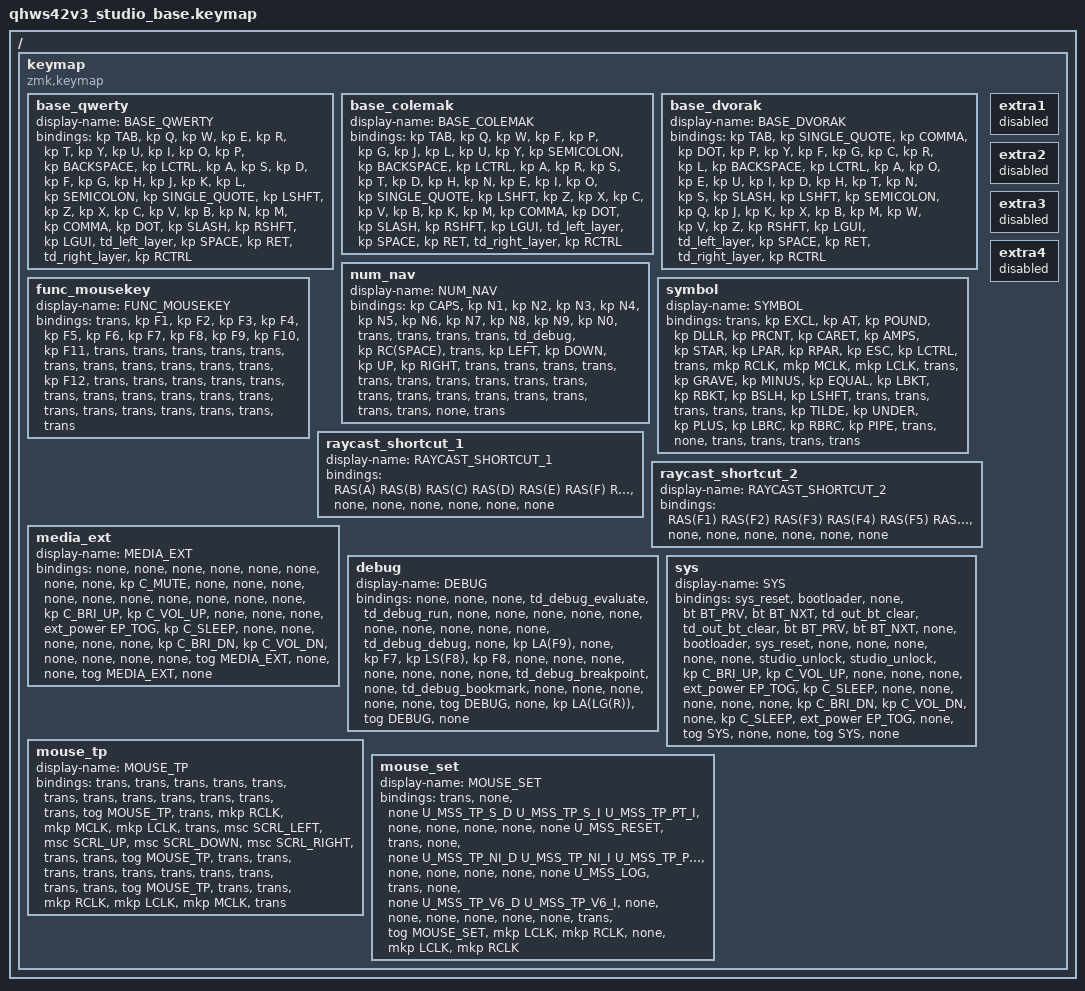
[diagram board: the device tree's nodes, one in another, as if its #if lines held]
/*
 * Copyright (c) 2020 The ZMK Contributors
 *
 * SPDX-License-Identifier: MIT
 */

// Define layer numbers
#define BASE_QWERTY 0
#define BASE_COLEMAK 1
#define BASE_DVORAK 2

#define NUM_NAV 3
#define SYMBOL 4
#define FUNC_MOUSEKEY 5

#define RAYCAST_SHORTCUT_1 6
#define RAYCAST_SHORTCUT_2 7

// 亮度，声音，macro
#define MEDIA_EXT 8
// idea debug
#define DEBUG 9
#define SYS 10

#define MOUSE_TP 11
#define MOUSE_SET 12


// ZMK includes
#include <behaviors.dtsi>
#include <dt-bindings/zmk/keys.h>
#include <dt-bindings/zmk/bt.h>
#include <dt-bindings/zmk/rgb.h>
#include <dt-bindings/zmk/ext_power.h>


// Personal includes
// #ifdef HAS_MOUSE_KEYS
//      #include "includes/mouse_keys.dtsi"
// #endif
// 
// #ifdef HAS_MOUSE_TP
//      #include "includes/mouse_tp.dtsi"
// #endif
#ifdef HAS_MOUSE_KEYS
    #include <dt-bindings/zmk/mouse.h>
#endif

// #include "includes/custom_keycodes.dtsi"
#include "includes/settings.dtsi"
//#include "includes/settings_pd.dtsi"
// #include "includes/conditional_layers.dtsi"
// #include "includes/macros.dtsi"
// #include "includes/combos.dtsi"
// #include "includes/behaviours_homerow_mods.dtsi"
// #include "includes/behaviours_mod_morph.dtsi"
// #include "includes/behaviours_other.dtsi"


#include "includes/qh_conditional_layers_v2.dtsi"
#include "includes/qh_combos_v2.dtsi"
#include "includes/qh_behaviours_other_v2.dtsi"

// raycast shortcut
#define RAS(X)  &kp LS(LC(LA(LG(X))))

// &none            &none           &none           &none           &none           &none               &none           &none           &none           &none           &none           &none
// &none            &none           &none           &none           &none           &none               &none           &none           &none           &none           &none           &none
// &none            &none           &none           &none           &none           &none               &none           &none           &none           &none           &none           &none
//                                                  &none           &none           &none               &none           &none           &none

// &tran            &trans          &trans          &trans          &trans          &trans              &trans          &trans          &trans          &trans          &trans          &trans
// &tran            &trans          &trans          &trans          &trans          &trans              &trans          &trans          &trans          &trans          &trans          &trans
// &tran            &trans          &trans          &trans          &trans          &trans              &trans          &trans          &trans          &trans          &trans          &trans
//                                                  &trans          &trans          &trans              &trans          &trans          &trans

/ {

  keymap {
    compatible = "zmk,keymap";

        base_qwerty {
            display-name = "BASE_QWERTY";
            bindings = <
                &kp TAB    &kp Q  &kp W     &kp E     &kp R                     &kp T               &kp Y    &kp U              &kp I      &kp O    &kp P          &kp BACKSPACE
                &kp LCTRL  &kp A  &kp S     &kp D     &kp F                     &kp G               &kp H    &kp J              &kp K      &kp L    &kp SEMICOLON  &kp SINGLE_QUOTE
                &kp LSHFT  &kp Z  &kp X     &kp C     &kp V                     &kp B               &kp N    &kp M              &kp COMMA  &kp DOT  &kp SLASH      &kp RSHFT
                                            &kp LGUI  &td_left_layer            &kp SPACE           &kp RET  &td_right_layer    &kp RCTRL
            >;
        };

        base_colemak {
            display-name = "BASE_COLEMAK";
            bindings = <
                &kp TAB    &kp Q  &kp W     &kp F     &kp P                     &kp G               &kp J    &kp L              &kp U      &kp Y    &kp SEMICOLON   &kp BACKSPACE
                &kp LCTRL  &kp A  &kp R     &kp S     &kp T                     &kp D               &kp H    &kp N              &kp E      &kp I    &kp O           &kp SINGLE_QUOTE
                &kp LSHFT  &kp Z  &kp X     &kp C     &kp V                     &kp B               &kp K    &kp M              &kp COMMA  &kp DOT  &kp SLASH       &kp RSHFT
                                            &kp LGUI  &td_left_layer            &kp SPACE           &kp RET  &td_right_layer    &kp RCTRL
            >;
        };

        base_dvorak {
            display-name = "BASE_DVORAK";
            bindings = <
                &kp TAB    &kp SINGLE_QUOTE &kp COMMA   &kp DOT   &kp P         &kp Y               &kp F    &kp G                  &kp C      &kp R  &kp L  &kp BACKSPACE
                &kp LCTRL  &kp A            &kp O       &kp E     &kp U         &kp I               &kp D    &kp H                  &kp T      &kp N  &kp S  &kp SLASH
                &kp LSHFT  &kp SEMICOLON    &kp Q       &kp J     &kp K         &kp X               &kp B    &kp M                  &kp W      &kp V  &kp Z  &kp RSHFT
                                            &kp LGUI    &td_left_layer          &kp SPACE           &kp RET  &td_right_layer    &kp RCTRL
            >;
        };

        num_nav {
            display-name = "NUM_NAV";
            bindings = <
                &kp CAPS    &kp N1      &kp N2      &kp N3       &kp N4        &kp N5          &kp N6    &kp N7    &kp N8     &kp N9     &kp N0  &trans
                &trans      &trans      &trans      &td_debug    &kp RC(SPACE) &trans          &kp LEFT  &kp DOWN  &kp UP     &kp RIGHT  &trans  &trans
                &trans      &trans      &trans      &trans       &trans        &trans          &trans    &trans    &trans     &trans     &trans  &trans
                                                    &trans       &trans        &trans          &trans    &none    &trans
            >;
        };

#ifdef HAS_MOUSE_KEYS
        symbol {
            display-name = "SYMBOL";
            bindings = <
                &trans      &kp EXCL      &kp AT      &kp POUND     &kp DLLR      &kp PRCNT                 &kp CARET       &kp AMPS        &kp STAR    &kp LPAR    &kp RPAR    &kp ESC
                &kp LCTRL   &trans        &mkp RCLK   &mkp MCLK     &mkp LCLK     &trans                    &kp GRAVE       &kp MINUS       &kp EQUAL   &kp LBKT    &kp RBKT    &kp BSLH
                &kp LSHFT   &trans        &trans      &trans        &trans        &trans                    &kp TILDE       &kp UNDER       &kp PLUS    &kp LBRC    &kp RBRC    &kp PIPE
                                                      &trans        &none        &trans                    &trans          &trans          &trans
            >;
        };
        func_mousekey {
            display-name = "FUNC_MOUSEKEY";
            bindings = <
                &trans  &kp F1  &kp F2      &kp F3     &kp F4      &kp F5              &kp F6          &kp F7          &kp F8          &kp F9          &kp F10  &kp F11
                &trans  &trans  &trans      &trans     &trans      &trans              &trans          &trans          &trans          &trans          &trans   &kp F12
                &trans  &trans  &trans      &trans     &trans      &trans              &trans          &trans          &trans          &trans          &trans   &trans
                                            &trans      &trans      &trans             &trans          &trans          &trans
            >;
        };
#else
        symbol {
            display-name = "SYMBOL";
            bindings = <
                &trans      &kp LS(EXCL)  &kp LS(AT)  &kp LS(POUND)  &kp LS(DLLR)  &kp LS(PRCNT)        &kp LS(CARET)  &kp LS(AMPS)   &kp LS(STAR)  &kp LS(LPAR)        &kp LS(RPAR)       &kp ESC
                &kp LCTRL   &trans        &trans      &trans         &trans        &trans               &kp GRAVE      &kp MINUS      &kp EQUAL     &kp LBKT            &kp RIGHT_BRACKET  &kp BSLH
                &kp LSHFT   &trans        &trans      &trans         &trans        &trans               &kp LS(TILDE)  &kp LS(UNDER)  &kp LS(PLUS)  &kp LS(LEFT_BRACE)  &kp LS(RBRC)       &kp LS(PIPE)
                                                      &trans         &none        &trans               &trans         &trans         &trans
            >;
        };
        func_mousekey {
            display-name = "FUNC_MOUSEKEY";
            bindings = <
                &trans  &kp F1  &kp F2  &kp F3  &kp F4  &kp F5          &kp F6  &kp F7  &kp F8  &kp F9   &kp F10 &kp F11
                &trans  &trans  &trans  &trans  &trans  &trans          &trans  &trans  &trans  &trans   &trans  &kp F12
                &trans  &trans  &trans  &trans  &trans  &trans          &trans  &trans  &trans  &trans   &trans  &trans
                                        &trans  &trans  &trans          &trans  &trans  &trans
            >;
        };
#endif

        raycast_shortcut_1 {
            display-name = "RAYCAST_SHORTCUT_1";
            bindings = <
                RAS(A)  RAS(B)  RAS(C)     RAS(D)     RAS(E)      RAS(F)               RAS(G)       RAS(H)    RAS(I)   RAS(J)   RAS(K)   RAS(L)
                RAS(M)  RAS(N)  RAS(O)     RAS(P)     RAS(LNLCK)      RAS(R)               RAS(S)       RAS(T)    RAS(U)   RAS(V)   RAS(W)   RAS(X)
                RAS(Y)  RAS(Z)  RAS(N1)    RAS(N2)    RAS(N3)     RAS(N4)              RAS(N5)      RAS(N6)   RAS(N7)  RAS(N8)  RAS(N9)  RAS(N0)
                                           &none      &none       &none                &none        &none     &none
            >;
        };

        raycast_shortcut_2 {
            display-name = "RAYCAST_SHORTCUT_2";
            bindings = <                   
                RAS(F1)    RAS(F2)  RAS(F3)       RAS(F4)     RAS(F5)       RAS(F6)           RAS(F7)        RAS(F8)     RAS(F9)     RAS(F10)    RAS(F11)   RAS(F12)
                RAS(INS)   RAS(HOME) RAS(PG_UP)      RAS(DEL)    RAS(END)      RAS(PG_DN)          RAS(GRAVE)       RAS(MINUS)    RAS(EQUAL)  RAS(LBKT)  RAS(RBKT) RAS(BSLH)
                RAS(SEMI)  RAS(SQT) RAS(PSCRN)    RAS(SLCK)    RAS(PAUSE_BREAK)     RAS(UP)           RAS(DOWN)      RAS(LEFT)   RAS(RIGHT)  RAS(RET)    RAS(SPACE) RAS(TAB)
                                                  &none       &none         &none             &none          &none       &none
            >;
        };

        media_ext {
            display-name = "MEDIA_EXT";
            bindings = <
                &none               &none           &none       &none       &none           &none                       &none               &none           &kp C_MUTE      &none       &none           &none
                &none               &none           &none       &none       &none           &none                       &none               &kp C_BRI_UP    &kp C_VOL_UP    &none       &none           &none
                &ext_power EP_TOG   &kp C_SLEEP     &none       &none       &none           &none                       &none               &kp C_BRI_DN    &kp C_VOL_DN    &none       &none     &none
                                                                &none       &tog MEDIA_EXT  &none                       &none               &tog MEDIA_EXT      &none
            >;
        };

// LA(F9) run to cursor
// LA(LG(R)) resume program
        debug {
            display-name = "DEBUG";
            bindings = <
                &none               &none           &none       &td_debug_evaluate      &td_debug_run   &none                           &none               &none               &none       &none       &none           &none
                &none               &none           &none       &td_debug_debug         &none           &kp LA(F9)                      &none               &kp F7              &kp LS(F8)  &kp F8      &none           &none
                &none               &none           &none       &none                   &none           &td_debug_breakpoint            &none               &td_debug_bookmark  &none       &none       &none           &none
                                                                &none                   &tog DEBUG      &none                           &kp LA(LG(R))       &tog DEBUG          &none
            >;
        };

        sys {
            display-name = "SYS";
            bindings = <
                &sys_reset          &bootloader     &none       &bt BT_PRV  &bt BT_NXT      &td_out_bt_clear            &td_out_bt_clear    &bt BT_PRV      &bt BT_NXT      &none       &bootloader     &sys_reset
                &none               &none           &none       &none       &none           &studio_unlock              &studio_unlock      &kp C_BRI_UP    &kp C_VOL_UP    &none       &none           &none
                &ext_power EP_TOG   &kp C_SLEEP     &none       &none       &none           &none                       &none               &kp C_BRI_DN    &kp C_VOL_DN    &none       &kp C_SLEEP     &ext_power EP_TOG
                                                                &none       &tog SYS  &none                       &none               &tog SYS  &none
            >;
        };

#if defined(HAS_MOUSE_KEYS) && defined(HAS_MOUSE_TP)
        mouse_tp {
            display-name = "MOUSE_TP";
            bindings = <
                &trans              &trans      &trans      &trans      &trans          &trans                  &trans          &trans          &trans          &trans              &trans          &trans
                &tog MOUSE_TP       &trans      &mkp RCLK   &mkp MCLK   &mkp LCLK       &trans                  &msc SCRL_LEFT  &msc SCRL_UP    &msc SCRL_DOWN  &msc SCRL_RIGHT     &trans          &trans
                &tog MOUSE_TP       &trans      &trans      &trans      &trans          &trans                  &trans          &trans          &trans          &trans              &trans          &tog MOUSE_TP
                                                            &trans      &trans          &mkp RCLK               &mkp LCLK       &mkp MCLK       &trans

            >;
        };
        mouse_set {
            display-name = "MOUSE_SET";
            bindings = <
                &trans  &none   &none   U_MSS_TP_S_D    U_MSS_TP_S_I    U_MSS_TP_PT_I                 &none                    &none                    &none                    &none                    &none                     U_MSS_RESET
                &trans  &none   &none   U_MSS_TP_NI_D   U_MSS_TP_NI_I   U_MSS_TP_PT_D                 &none                    &none                    &none                    &none                    &none                     U_MSS_LOG
                &trans  &none   &none   U_MSS_TP_V6_D   U_MSS_TP_V6_I   &none                         &none                    &none                    &none                    &none                    &none                     &trans
                                        &tog MOUSE_SET  &mkp LCLK       &mkp RCLK                     &none                    &mkp LCLK                &mkp RCLK
            >;
        };
#endif

    extra1 {
        status = "reserved";
    };
    extra2 {
        status = "reserved";
    };
    extra3 {
        status = "reserved";
    };
    extra4 {
        status = "reserved";
    };
  };

};
